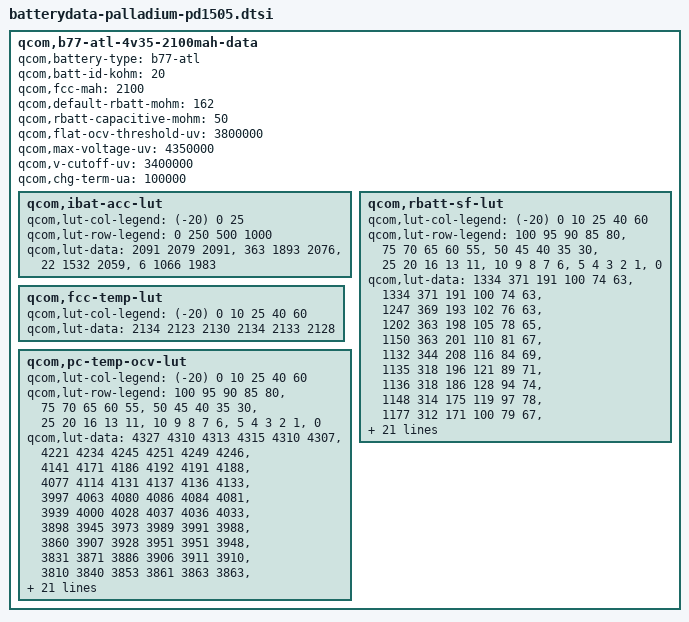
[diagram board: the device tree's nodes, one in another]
/* Copyright (c) 2013-2014, The Linux Foundation. All rights reserved.
 *
 * This program is free software; you can redistribute it and/or modify
 * it under the terms of the GNU General Public License version 2 and
 * only version 2 as published by the Free Software Foundation.
 *
 * This program is distributed in the hope that it will be useful,
 * but WITHOUT ANY WARRANTY; without even the implied warranty of
 * MERCHANTABILITY or FITNESS FOR A PARTICULAR PURPOSE.  See the
 * GNU General Public License for more details.
 */

qcom,b77-atl-4v35-2100mah-data {
	qcom,battery-type = "b77-atl";
	qcom,batt-id-kohm = <20>;
	qcom,fcc-mah = <2100>;
	qcom,default-rbatt-mohm = <162>;
	qcom,rbatt-capacitive-mohm = <50>;
	qcom,flat-ocv-threshold-uv = <3800000>;
	qcom,max-voltage-uv = <4350000>;
	qcom,v-cutoff-uv = <3400000>;
	qcom,chg-term-ua = <100000>;

	qcom,ibat-acc-lut {
		qcom,lut-col-legend = <(-20) 0 25>;
		qcom,lut-row-legend = <0 250 500 1000>;
		qcom,lut-data = <2091 2079 2091>,
				<363 1893 2076>,
				<22 1532 2059>,
				<6 1066 1983>;
	};
	qcom,rbatt-sf-lut {
		qcom,lut-col-legend = <(-20) 0 10 25 40 60>;
		qcom,lut-row-legend = <100 95 90 85 80>,
				<75 70 65 60 55>,
				<50 45 40 35 30>,
				<25 20 16 13 11>,
				<10 9 8 7 6>,
				<5 4 3 2 1>,
				<0>;
		qcom,lut-data = <1334 371 191 100 74 63>,
				<1334 371 191 100 74 63>,
				<1247 369 193 102 76 63>,
				<1202 363 198 105 78 65>,
				<1150 363 201 110 81 67>,
				<1132 344 208 116 84 69>,
				<1135 318 196 121 89 71>,
				<1136 318 186 128 94 74>,
				<1148 314 175 119 97 78>,
				<1177 312 171 100 79 67>,
				<1221 313 171 97 74 64>,
				<1277 319 172 98 75 65>,
				<1348 334 173 101 78 67>,
				<1432 356 180 102 81 70>,
				<1534 385 192 106 80 69>,
				<1677 421 206 108 78 64>,
				<1963 476 220 108 76 64>,
				<2369 547 235 110 78 65>,
				<2673 618 248 109 77 64>,
				<2541 620 254 109 76 64>,
				<2799 649 266 111 78 65>,
				<3131 689 283 115 81 67>,
				<3549 736 304 121 84 68>,
				<4062 788 331 127 87 70>,
				<4736 851 360 134 89 70>,
				<5647 916 392 138 87 68>,
				<6911 995 428 140 87 68>,
				<8815 1100 490 151 92 71>,
				<12604 1269 598 174 102 80>,
				<26360 2997 3364 253 161 141>,
				<26360 2997 3364 253 161 141>;
	};

	qcom,fcc-temp-lut {
		qcom,lut-col-legend = <(-20) 0 10 25 40 60>;
		qcom,lut-data = <2134 2123 2130 2134 2133 2128>;
	};

	qcom,pc-temp-ocv-lut {
		qcom,lut-col-legend = <(-20) 0 10 25 40 60>;
		qcom,lut-row-legend = <100 95 90 85 80>,
				<75 70 65 60 55>,
				<50 45 40 35 30>,
				<25 20 16 13 11>,
				<10 9 8 7 6>,
				<5 4 3 2 1>,
				<0>;
				
		qcom,lut-data =					
		                <4327 4310 4313 4315 4310 4307>,
				<4221 4234 4245 4251 4249 4246>,
				<4141 4171 4186 4192 4191 4188>,
				<4077 4114 4131 4137 4136 4133>,
				<3997 4063 4080 4086 4084 4081>,
				<3939 4000 4028 4037 4036 4033>,
				<3898 3945 3973 3989 3991 3988>,
				<3860 3907 3928 3951 3951 3948>,
				<3831 3871 3886 3906 3911 3910>,
				<3810 3840 3853 3861 3863 3863>,
				<3794 3814 3826 3831 3832 3832>,
				<3781 3794 3804 3809 3810 3809>,
				<3768 3780 3786 3791 3792 3791>,
				<3753 3769 3775 3777 3777 3776>,
				<3738 3757 3765 3767 3763 3758>,
				<3720 3740 3754 3754 3747 3734>,
				<3697 3718 3733 3735 3726 3713>,
				<3676 3701 3710 3711 3702 3691>,
				<3657 3689 3688 3687 3680 3669>,
				<3644 3680 3679 3678 3672 3661>,
				<3634 3674 3675 3675 3670 3659>,
				<3623 3668 3671 3673 3667 3657>,
				<3610 3661 3667 3670 3665 3654>,
				<3593 3652 3662 3665 3660 3650>,
				<3574 3638 3651 3657 3651 3639>,
				<3548 3611 3629 3634 3624 3611>,
				<3514 3567 3585 3590 3576 3562>,
				<3465 3502 3519 3526 3511 3498>,
				<3391 3406 3426 3438 3422 3411>,
				<3271 3248 3283 3304 3285 3271>,
				<3000 3030 3000 3000 3000 3000>;
	};
};
